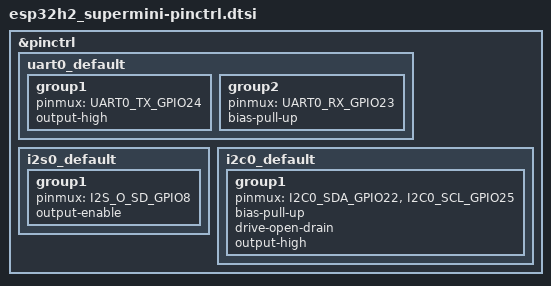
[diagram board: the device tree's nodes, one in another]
/*
 * Copyright (c) 2026 Ivan Shautsou
 * SPDX-License-Identifier: Apache-2.0
 */

#include <zephyr/dt-bindings/pinctrl/esp32h2-pinctrl.h>

&pinctrl {
	uart0_default: uart0_default {
		group1 {
			pinmux = <UART0_TX_GPIO24>;
			output-high;
		};

		group2 {
			pinmux = <UART0_RX_GPIO23>;
			bias-pull-up;
		};
	};

	i2s0_default: i2s0_default {
		group1 {
			pinmux = <I2S_O_SD_GPIO8>;
			output-enable;
		};
	};

	i2c0_default: i2c0_default {
		group1 {
			pinmux = <I2C0_SDA_GPIO22>,
				 <I2C0_SCL_GPIO25>;
			bias-pull-up;
			drive-open-drain;
			output-high;
		};
	};
};
